# MCXA156 register map
Vendor: nxp.com; File version: 1.0
CPU: CM33 r2p0, little endian, no MPU, FPU, VTOR, 3 interrupt priority bits
Registers are 32-bit, read-write, reset 0x0 unless marked. A register's access mark holds for its fields unless they carry their own. Offsets are from the block's base; [hi:lo] are bit positions; {n}, {i} and the like mark numbered series; 'fields as' and 'values as' point back to an identical list.

## SYSCON
Base 0x40091000; alternate view of MRCC0
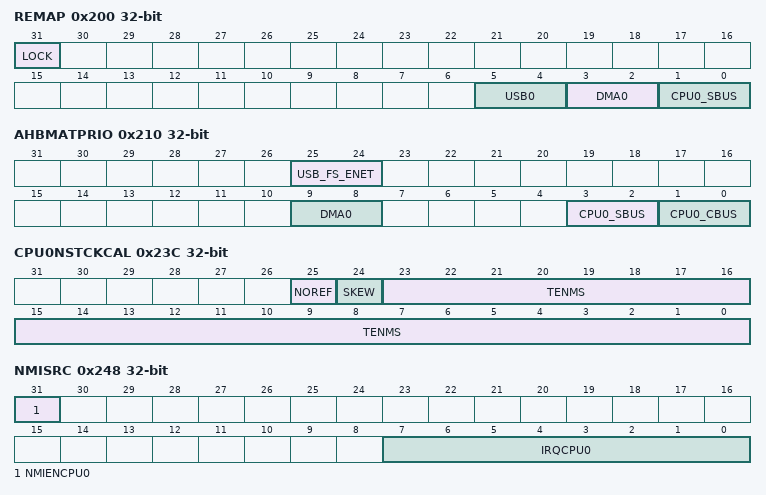
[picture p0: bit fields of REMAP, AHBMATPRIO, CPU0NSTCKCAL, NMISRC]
0x200 REMAP — AHB Matrix Remap Control
  [31] LOCK — This 1-bit field provides a mechanism to limit writes to the this register to protect its contents. Once set, this bit remains asserted until a system reset.
    0=This register is not locked and can be altered; 1=This register is locked and cannot be altered until a system reset
  [5:4] USB0 — RAMX0 address remap for USB0
    0=RAMX0: 0x04000000 - 0x04001fff; 1=RAMX0: same alias space as CPU0_SBUS
  [3:2] DMA0 — RAMX0 address remap for DMA0
    values as USB0
  [1:0] CPU0_SBUS — RAMX0 address remap for CPU System bus
    0=RAMX0: 0x04000000 - 0x04001fff; 1=RAMX0: 0x2001e000 - 0x2001ffff(for 128KB RAM chip) / 0x20016000 - 0x20017fff(for 96KB RAM chip) / 0x2000e000 - 0x2000ffff(for 64KB RAM chip)
0x210 AHBMATPRIO — AHB Matrix Priority Control
  [all] fields
    {v}=LEVEL{v} (v=0..3)
  [25:24] USB_FS_ENET — USB-FS bus master priority level
  [9:8] DMA0 — DMA0 controller bus master priority level
  [3:2] CPU0_SBUS — CPU0 S-AHB bus master priority level
  [1:0] CPU0_CBUS — CPU0 C-AHB bus master priority level
0x23C CPU0NSTCKCAL — Non-Secure CPU0 System Tick Calibration
  [25] NOREF — Indicates whether the device provides a reference clock to the processor.
    0=YES_REF (Reference clock is provided); 1=NO_REF (No reference clock is provided)
  [24] SKEW — Indicates whether the TENMS value is exact.
    0=EXACT (TENMS value is exact); 1=INEXACT (TENMS value is not exact or not given)
  [23:0] TENMS — Reload value for 10 ms (100 Hz) timing, subject to system clock skew errors. If the value reads as zero, the calibration value is not known.
0x248 NMISRC — NMI Source Select
  [31] NMIENCPU0 — Enables the Non-Maskable Interrupt (NMI) source selected by IRQCPU0.
    0=DISABLE; 1=ENABLE
  [7:0] IRQCPU0 — The IRQ number of the interrupt that acts as the Non-Maskable Interrupt (NMI) for CPU0, if enabled by NMIENCPU0.
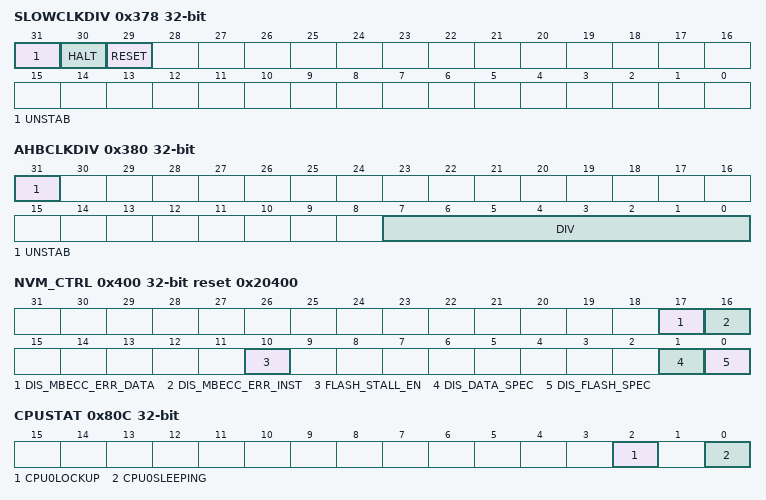
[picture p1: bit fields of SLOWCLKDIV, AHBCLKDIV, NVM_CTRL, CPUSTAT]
0x378 SLOWCLKDIV — SLOW_CLK Clock Divider
  [31] UNSTAB ro — Divider status flag
    0=STABLE (Divider clock is stable); 1=ONGOING (Clock frequency is not stable)
  [30] HALT — Halts the divider counter
    0=RUN (Divider clock is running); 1=HALT (Divider clock is stopped)
  [29] RESET — Resets the divider counter
    0=RELEASED (Divider is not reset); 1=ASSERTED (Divider is reset)
0x380 AHBCLKDIV — System Clock Divider
  [31] UNSTAB ro — Divider status flag
    values as SLOWCLKDIV.UNSTAB
  [7:0] DIV — Clock divider value
0x3FC CLKUNLOCK — Clock Configuration Unlock
  [0] UNLOCK — Controls clock configuration registers access (for example, MRCC_xxx_CLKDIV, MRCC_xxx_CLKSEL, MRCC_GLB_xxx)
    0=ENABLE (Updates are allowed to all clock configuration registers); 1=FREEZE (Freezes all clock configuration registers update.)
0x400 NVM_CTRL reset 0x20400 — NVM Control
  [17] DIS_MBECC_ERR_DATA — Bus error on data multi-bit ECC error control Set this field to 0 if you want to enable flash speculative
    0=ENABLE (Enables bus error on multi-bit ECC error for data); 1=DISABLE (Disables bus error on multi-bit ECC error for data)
  [16] DIS_MBECC_ERR_INST — Bus error on data multi-bit ECC error control Set this field to 0 if you want to enable flash speculative
    0=ENABLE (Enables bus error on multi-bit ECC error for instruction); 1=DISABLE (Disables bus error on multi-bit ECC error for instruction)
  [10] FLASH_STALL_EN — FLASH stall on busy control
    0=ENABLE (No stall on FLASH busy); 1=DISABLE (Stall on FLASH busy)
  [1] DIS_DATA_SPEC — Flash data speculation control
    0=ENABLE (Enables data speculation); 1=DISABLE (Disables data speculation)
  [0] DIS_FLASH_SPEC — Flash speculation control
    0=ENABLE (Enables flash speculation); 1=DISABLE (Disables flash speculation)
0x404 ROMCR ro — ROM Wait State
0x80C CPUSTAT ro — CPU Status
  [2] CPU0LOCKUP — CPU0 lockup state
    0=AWAKE (CPU is not in lockup); 1=SLEEPING (CPU is in lockup)
  [0] CPU0SLEEPING — CPU0 sleeping state
    0=AWAKE (CPU is not sleeping); 1=SLEEPING (CPU is sleeping)
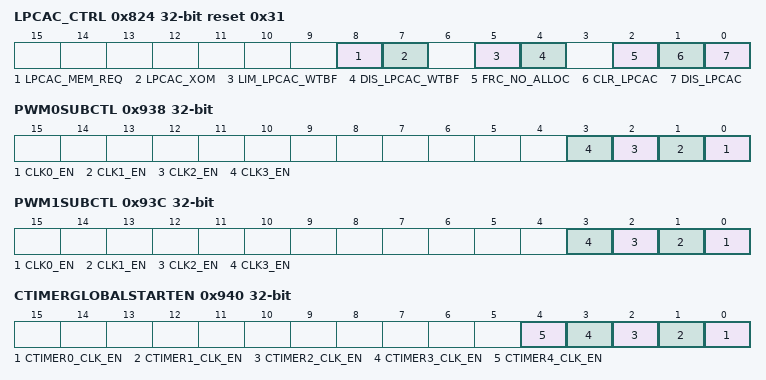
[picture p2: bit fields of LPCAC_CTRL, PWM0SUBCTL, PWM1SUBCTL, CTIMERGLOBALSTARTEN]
0x824 LPCAC_CTRL reset 0x31 — LPCAC Control
  [8] LPCAC_MEM_REQ — Request LPCAC memories.
    0=DISABLE (Configure shared memories RAMX1 as general memories.); 1=ENABLE (Configure shared memories RAMX1 as LPCAC memories, write one lock until a system reset.)
  [7] LPCAC_XOM — LPCAC XOM(eXecute-Only-Memory) attribute control
    0=DISABLE (Disabled.); 1=ENABLE (Enabled.)
  [5] LIM_LPCAC_WTBF — Limit LPCAC Write Through Buffer.
    0=DISABLE (Write buffer enabled when transaction is bufferable.); 1=ENABLE (Write buffer enabled when transaction is cacheable and bufferable)
  [4] DIS_LPCAC_WTBF — Disable LPCAC Write Through Buffer.
    0=DISABLE (Enables write through buffer); 1=ENABLE (Disables write through buffer)
  [2] FRC_NO_ALLOC — Forces no allocation.
    0=ENABLE (Forces allocation); 1=DISABLE (Forces no allocation)
  [1] CLR_LPCAC — Clears the cache function.
    0=ENABLE (Unclears the cache); 1=DISABLE (Clears the cache)
  [0] DIS_LPCAC — Disables/enables the cache function.
    0=ENABLE (Enabled); 1=DISABLE (Disabled)
0x938 PWM0SUBCTL — PWM0 Submodule Control
  [all] fields
    0=DISABLE; 1=ENABLE
  [n] CLK{n}_EN (n=0..3) — Enables PWM0 SUB Clock{n}
0x93C PWM1SUBCTL — PWM1 Submodule Control
  [all] fields
    0=DISABLE; 1=ENABLE
  [n] CLK{n}_EN (n=0..3) — Enables PWM1 SUB Clock{n}
0x940 CTIMERGLOBALSTARTEN — CTIMER Global Start Enable
  [all] fields
    0=DISABLE; 1=ENABLE
  [n] CTIMER{n}_CLK_EN (n=0..4) — Enables the CTIMER{n} function clock
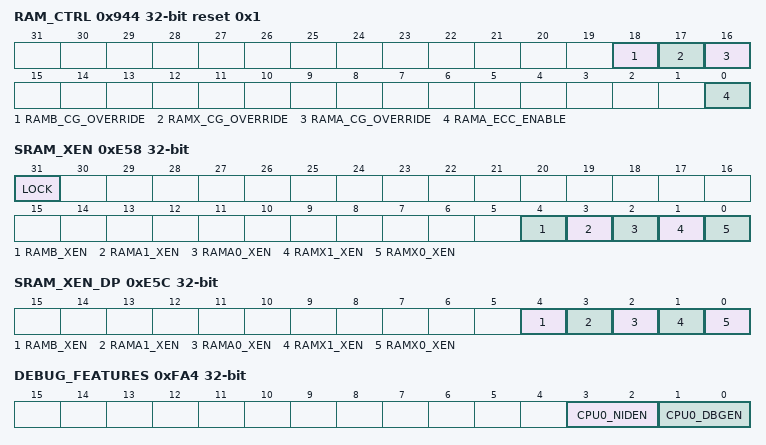
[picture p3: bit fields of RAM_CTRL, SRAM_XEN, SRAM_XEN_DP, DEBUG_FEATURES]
0x944 RAM_CTRL reset 0x1 — RAM Control
  [18] RAMB_CG_OVERRIDE — RAMB bank clock gating control
    0=DISABLE (Memory bank clock is gated automatically if no access more than 16 clock cycles); 1=ENABLE (Auto clock gating feature is disabled)
  [17] RAMX_CG_OVERRIDE — RAMX bank clock gating control
    values as RAMB_CG_OVERRIDE
  [16] RAMA_CG_OVERRIDE — RAMA bank clock gating control, only avaiable when RAMA_ECC_ENABLE = 0.
    values as RAMB_CG_OVERRIDE
  [0] RAMA_ECC_ENABLE — RAMA0 ECC enable
    0=DISABLE (ECC is disabled); 1=ENABLE (ECC is enabled)
0xB60 GRAY_CODE_LSB — Gray to Binary Converter Gray Code [31:0]
  [31:0] code_gray_31_0 — Gray code [31:0]
0xB64 GRAY_CODE_MSB — Gray to Binary Converter Gray Code [41:32]
  [9:0] code_gray_41_32 — Gray code [41:32]
0xB68 BINARY_CODE_LSB ro — Gray to Binary Converter Binary Code [31:0]
  [31:0] code_bin_31_0 — Binary code [31:0]
0xB6C BINARY_CODE_MSB ro — Gray to Binary Converter Binary Code [41:32]
  [9:0] code_bin_41_32 — Binary code [41:32]
0xE3C ROP_STATE ro reset not defined
0xE40 OVP_PAD_STATE ro reset not defined
0xE44 PROBE_STATE ro reset not defined
0xE48 FT_STATE_A ro reset not defined
0xE4C FT_STATE_B ro reset not defined
0xE58 SRAM_XEN — RAM XEN Control
  [31] LOCK — This 1-bit field provides a mechanism to limit writes to the this register (and SRAM_XEN_DP) to protect its contents. Once set, this bit remains asserted until a system reset.
    0=This register is not locked and can be altered; 1=This register is locked and cannot be altered
  [4] RAMB_XEN — RAMBx Execute permission control.
    0=DISABLE (Execute permission is disabled, R/W are enabled.); 1=ENABLE (Execute permission is enabled, R/W/X are enabled.)
  [3] RAMA1_XEN — RAMAx (excepts RAMA0) Execute permission control.
    values as RAMB_XEN
  [2] RAMA0_XEN — RAMA0 Execute permission control.
    values as RAMB_XEN
  [1] RAMX1_XEN — RAMX1 Execute permission control.
    values as RAMB_XEN
  [0] RAMX0_XEN — RAMX0 Execute permission control.
    values as RAMB_XEN
0xE5C SRAM_XEN_DP — RAM XEN Control (Duplicate)
  [4] RAMB_XEN — Refer to SRAM_XEN for more details.
  [3] RAMA1_XEN — Refer to SRAM_XEN for more details.
  [2] RAMA0_XEN — Refer to SRAM_XEN for more details.
  [1] RAMX1_XEN — Refer to SRAM_XEN for more details.
  [0] RAMX0_XEN — Refer to SRAM_XEN for more details.
0xE80 ELS_OTP_LC_STATE ro (reset mask 0xFFFFFF00) — Life Cycle State Register
  [7:0] OTP_LC_STATE — OTP life cycle state
0xE84 ELS_OTP_LC_STATE_DP ro (reset mask 0xFFFFFF00) — Life Cycle State Register (Duplicate)
  [7:0] OTP_LC_STATE_DP — OTP life cycle state
0xFA0 DEBUG_LOCK_EN reset 0xA — Control Write Access to Security
  [3:0] LOCK_ALL — Controls write access to the security registers
    0=DISABLE (Any other value than b1010: disables write access to all registers); 10=ENABLE (Enables write access to all registers)
0xFA4 DEBUG_FEATURES reset not defined — Cortex Debug Features Control
  [3:2] CPU0_NIDEN — CPU0 non-invasive debug control
    1=DISABLE (Disables debug); 2=ENABLE (Enables debug)
  [1:0] CPU0_DBGEN — CPU0 invasive debug control
    1=DISABLE (Disables debug); 2=ENABLE (Enables debug)
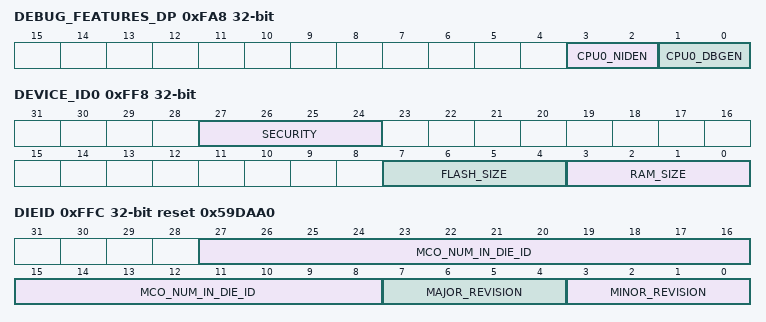
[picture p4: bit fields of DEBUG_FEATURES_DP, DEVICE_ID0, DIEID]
0xFA8 DEBUG_FEATURES_DP reset not defined — Cortex Debug Features Control (Duplicate)
  fields as DEBUG_FEATURES
0xFB4 SWD_ACCESS_CPU0 — CPU0 Software Debug Access
  [31:0] SEC_CODE — CPU0 SWD-AP: 0x12345678
    0=DISABLE (CPU0 DAP is not allowed. Reading back register is read as 0x5.); 0x12345678=ENABLE (Value to write to enable CPU0 SWD access. Reading back register is read as 0xA.)
0xFC0 DEBUG_AUTH_BEACON — Debug Authentication BEACON
  [31:0] BEACON — Sets by the debug authentication code in ROM to pass the debug beacons (Credential Beacon and Authentication Beacon) to the application code.
0xFF0 JTAG_ID ro reset 0x726702B — JTAG Chip ID
  [31:0] JTAG_ID — Indicates the device ID
0xFF4 DEVICE_TYPE ro reset 0x2000 (reset mask 0xF000)
  [31:0] DEVICE_TYPE — Indicates DEVICE TYPE.
0xFF8 DEVICE_ID0 ro (reset mask 0xF00FFF00) — Device ID
  [27:24] SECURITY
    5=NON_SEC (Secure version.); 10=Non secure version
  [7:4] FLASH_SIZE — Chip FLASH Size
    0=SIZE_32KB (32KB.); 1=SIZE_64KB (64KB.); 2=SIZE_128KB (128KB.); 3=SIZE_256KB (256KB.); 4=SIZE_512KB (512KB.); 5=SIZE_768KB (768KB.); 6=SIZE_1MB (1MB.); 7=SIZE_1P5MB (1.5MB.); 8=SIZE_2MB (2MB.)
  [3:0] RAM_SIZE — Chip RAM Size
    0=SIZE_8KB (8KB.); 1=SIZE_16KB (16KB.); 2=SIZE_32KB (32KB.); 3=SIZE_64KB (64KB.); 4=SIZE_96KB (96KB.); 5=SIZE_128KB (128KB.); 6=SIZE_160KB (160KB.); 7=SIZE_192KB (192KB.); 8=SIZE_256KB (256KB.); 9=SIZE_288KB (288KB.); 10=SIZE_352KB (352KB.); 11=SIZE_512KB (512KB.)
0xFFC DIEID ro reset 0x59DAA0 — Chip Revision ID and Number
  [27:8] MCO_NUM_IN_DIE_ID — Chip number
  [7:4] MAJOR_REVISION — Chip major revision
  [3:0] MINOR_REVISION — Chip minor revision
